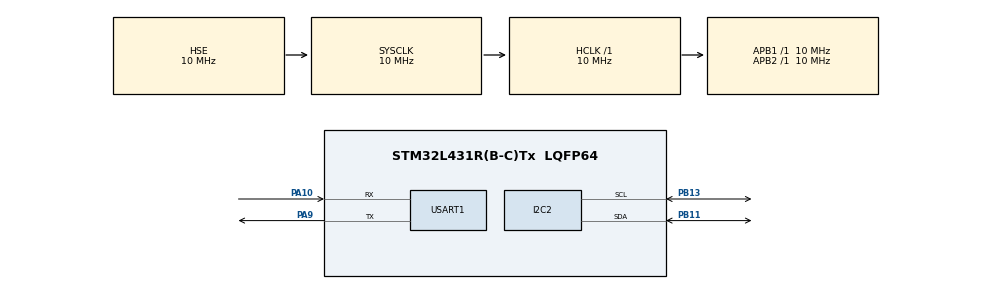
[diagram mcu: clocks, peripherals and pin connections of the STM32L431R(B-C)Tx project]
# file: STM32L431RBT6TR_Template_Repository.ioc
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FREERTOS.Tasks01=defaultTask,0,192,StartDefaultTask,Default,NULL,Dynamic,NULL,NULL
FREERTOS.configMINIMAL_STACK_SIZE=192
FREERTOS.configTOTAL_HEAP_SIZE=40000
FREERTOS.configUSE_NEWLIB_REENTRANT=1
FREERTOS.configUSE_TIMERS=1
I2C2.Timing=0x00302833
IWDG.Prescaler=IWDG_PRESCALER_16
Mcu.Family=STM32L4
Mcu.Name=STM32L431R(B-C)Tx
Mcu.Package=LQFP64
NVIC.PriorityGroup=NVIC_PRIORITYGROUP_4
NVIC.TIM1_UP_TIM16_IRQn=true\:15\:0\:false\:false\:true\:false\:false\:true\:true
NVIC.TimeBase=TIM1_UP_TIM16_IRQn
NVIC.TimeBaseIP=TIM1
NVIC.USART1_IRQn=true\:5\:0\:false\:false\:true\:true\:true\:true\:true
PA10.Mode=Asynchronous
PA10.Signal=USART1_RX
PA9.Mode=Asynchronous
PA9.Signal=USART1_TX
PB11.GPIO_Pu=GPIO_PULLUP
PB11.Mode=I2C
PB11.Signal=I2C2_SDA
PB13.GPIO_Pu=GPIO_PULLUP
PB13.Mode=I2C
PB13.Signal=I2C2_SCL
PH0-OSC_IN\ (PH0).Mode=HSE-External-Oscillator
PH0-OSC_IN\ (PH0).Signal=RCC_OSC_IN
PH1-OSC_OUT\ (PH1).Mode=HSE-External-Oscillator
PH1-OSC_OUT\ (PH1).Signal=RCC_OSC_OUT
ProjectManager.HeapSize=0x200
ProjectManager.StackSize=0x400
ProjectManager.TargetToolchain=STM32CubeIDE
RCC.ADCFreq_Value=16000000
RCC.AHBFreq_Value=10000000
RCC.APB1Freq_Value=10000000
RCC.APB1TimFreq_Value=10000000
RCC.APB2Freq_Value=10000000
RCC.APB2TimFreq_Value=10000000
RCC.CortexFreq_Value=10000000
RCC.HCLKFreq_Value=10000000
RCC.HSE_VALUE=10000000
RCC.HSI48_VALUE=48000000
RCC.HSI_VALUE=16000000
RCC.LSE_VALUE=32768
RCC.MSI_VALUE=4000000
RCC.SYSCLKFreq_VALUE=10000000
RCC.SYSCLKSource=RCC_SYSCLKSOURCE_HSE
RCC.VCOOutputFreq_Value=32000000
USART1.VirtualMode-Asynchronous=VM_ASYNC
VP_CRC_VS_CRC.Mode=CRC_Activate
VP_FREERTOS_VS_CMSIS_V1.Mode=CMSIS_V1
VP_IWDG_VS_IWDG.Mode=IWDG_Activate
VP_SYS_VS_tim1.Mode=TIM1
board=custom

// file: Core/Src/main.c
/* USER CODE BEGIN Header */
/**
  ******************************************************************************
  * @file           : main.c
  * @brief          : Main program body
  ******************************************************************************
  * @attention
  *
  * Copyright (c) 2025 STMicroelectronics.
  * All rights reserved.
  *
  * This software is licensed under terms that can be found in the LICENSE file
  * in the root directory of this software component.
  * If no LICENSE file comes with this software, it is provided AS-IS.
  *
  ******************************************************************************
  */
/* USER CODE END Header */
#include "main.h"
#include "cmsis_os.h"

/* USER CODE BEGIN Includes */
#include "RunInterface.hpp"
/* USER CODE END Includes */

CRC_HandleTypeDef hcrc;

I2C_HandleTypeDef hi2c2;

IWDG_HandleTypeDef hiwdg;

osThreadId defaultTaskHandle;

void SystemClock_Config(void);
static void MX_GPIO_Init(void);
static void MX_CRC_Init(void);
static void MX_USART1_UART_Init(void);
static void MX_I2C2_Init(void);
static void MX_IWDG_Init(void);
void StartDefaultTask(void const * argument);

int main(void)
{

  /* MCU Configuration--------------------------------------------------------*/

  /* Reset of all peripherals, Initializes the Flash interface and the Systick. */
  HAL_Init();

  /* Configure the system clock */
  SystemClock_Config();

  /* Initialize all configured peripherals */
  MX_GPIO_Init();
  MX_CRC_Init();
  MX_USART1_UART_Init();
  MX_I2C2_Init();
  MX_IWDG_Init();
  /* USER CODE BEGIN 2 */
  run_interface();
  #if 0
  /* USER CODE END 2 */

  /* Create the thread(s) */
  /* definition and creation of defaultTask */
  osThreadDef(defaultTask, StartDefaultTask, osPriorityNormal, 0, 192);
  defaultTaskHandle = osThreadCreate(osThread(defaultTask), NULL);

  /* Start scheduler */
  osKernelStart();

  /* We should never get here as control is now taken by the scheduler */

  /* Infinite loop */
  while (1)
  {

    /* USER CODE BEGIN 3 */
  }
#endif
  /* USER CODE END 3 */
}

void SystemClock_Config(void)
{
  RCC_OscInitTypeDef RCC_OscInitStruct = {0};
  RCC_ClkInitTypeDef RCC_ClkInitStruct = {0};

  /** Configure the main internal regulator output voltage
  */
  if (HAL_PWREx_ControlVoltageScaling(PWR_REGULATOR_VOLTAGE_SCALE1) != HAL_OK)
  {
    Error_Handler();
  }

  /** Initializes the RCC Oscillators according to the specified parameters
  * in the RCC_OscInitTypeDef structure.
  */
  RCC_OscInitStruct.OscillatorType = RCC_OSCILLATORTYPE_LSI|RCC_OSCILLATORTYPE_HSE;
  RCC_OscInitStruct.HSEState = RCC_HSE_ON;
  RCC_OscInitStruct.LSIState = RCC_LSI_ON;
  RCC_OscInitStruct.PLL.PLLState = RCC_PLL_NONE;
  if (HAL_RCC_OscConfig(&RCC_OscInitStruct) != HAL_OK)
  {
    Error_Handler();
  }

  /** Initializes the CPU, AHB and APB buses clocks
  */
  RCC_ClkInitStruct.ClockType = RCC_CLOCKTYPE_HCLK|RCC_CLOCKTYPE_SYSCLK
                              |RCC_CLOCKTYPE_PCLK1|RCC_CLOCKTYPE_PCLK2;
  RCC_ClkInitStruct.SYSCLKSource = RCC_SYSCLKSOURCE_HSE;
  RCC_ClkInitStruct.AHBCLKDivider = RCC_SYSCLK_DIV1;
  RCC_ClkInitStruct.APB1CLKDivider = RCC_HCLK_DIV1;
  RCC_ClkInitStruct.APB2CLKDivider = RCC_HCLK_DIV1;

  if (HAL_RCC_ClockConfig(&RCC_ClkInitStruct, FLASH_LATENCY_0) != HAL_OK)
  {
    Error_Handler();
  }
}

static void MX_CRC_Init(void)
{

  hcrc.Instance = CRC;
  hcrc.Init.DefaultPolynomialUse = DEFAULT_POLYNOMIAL_ENABLE;
  hcrc.Init.DefaultInitValueUse = DEFAULT_INIT_VALUE_ENABLE;
  hcrc.Init.InputDataInversionMode = CRC_INPUTDATA_INVERSION_NONE;
  hcrc.Init.OutputDataInversionMode = CRC_OUTPUTDATA_INVERSION_DISABLE;
  hcrc.InputDataFormat = CRC_INPUTDATA_FORMAT_BYTES;
  if (HAL_CRC_Init(&hcrc) != HAL_OK)
  {
    Error_Handler();
  }

}

static void MX_I2C2_Init(void)
{

  hi2c2.Instance = I2C2;
  hi2c2.Init.Timing = 0x00302833;
  hi2c2.Init.OwnAddress1 = 0;
  hi2c2.Init.AddressingMode = I2C_ADDRESSINGMODE_7BIT;
  hi2c2.Init.DualAddressMode = I2C_DUALADDRESS_DISABLE;
  hi2c2.Init.OwnAddress2 = 0;
  hi2c2.Init.OwnAddress2Masks = I2C_OA2_NOMASK;
  hi2c2.Init.GeneralCallMode = I2C_GENERALCALL_DISABLE;
  hi2c2.Init.NoStretchMode = I2C_NOSTRETCH_DISABLE;
  if (HAL_I2C_Init(&hi2c2) != HAL_OK)
  {
    Error_Handler();
  }

  /** Configure Analogue filter
  */
  if (HAL_I2CEx_ConfigAnalogFilter(&hi2c2, I2C_ANALOGFILTER_ENABLE) != HAL_OK)
  {
    Error_Handler();
  }

  /** Configure Digital filter
  */
  if (HAL_I2CEx_ConfigDigitalFilter(&hi2c2, 0) != HAL_OK)
  {
    Error_Handler();
  }

}

static void MX_IWDG_Init(void)
{

  hiwdg.Instance = IWDG;
  hiwdg.Init.Prescaler = IWDG_PRESCALER_16;
  hiwdg.Init.Window = 4095;
  hiwdg.Init.Reload = 4095;
  if (HAL_IWDG_Init(&hiwdg) != HAL_OK)
  {
    Error_Handler();
  }
  /* USER CODE BEGIN IWDG_Init 2 */
  HAL_IWDG_Refresh(&hiwdg);
  /* USER CODE END IWDG_Init 2 */

}

static void MX_USART1_UART_Init(void)
{

  LL_USART_InitTypeDef USART_InitStruct = {0};

  LL_GPIO_InitTypeDef GPIO_InitStruct = {0};
  RCC_PeriphCLKInitTypeDef PeriphClkInit = {0};

  /** Initializes the peripherals clock
  */
  PeriphClkInit.PeriphClockSelection = RCC_PERIPHCLK_USART1;
  PeriphClkInit.Usart1ClockSelection = RCC_USART1CLKSOURCE_PCLK2;
  if (HAL_RCCEx_PeriphCLKConfig(&PeriphClkInit) != HAL_OK)
  {
    Error_Handler();
  }

  /* Peripheral clock enable */
  LL_APB2_GRP1_EnableClock(LL_APB2_GRP1_PERIPH_USART1);

  LL_AHB2_GRP1_EnableClock(LL_AHB2_GRP1_PERIPH_GPIOA);
  /**USART1 GPIO Configuration
  PA9   ------> USART1_TX
  PA10   ------> USART1_RX
  */
  GPIO_InitStruct.Pin = LL_GPIO_PIN_9|LL_GPIO_PIN_10;
  GPIO_InitStruct.Mode = LL_GPIO_MODE_ALTERNATE;
  GPIO_InitStruct.Speed = LL_GPIO_SPEED_FREQ_VERY_HIGH;
  GPIO_InitStruct.OutputType = LL_GPIO_OUTPUT_PUSHPULL;
  GPIO_InitStruct.Pull = LL_GPIO_PULL_NO;
  GPIO_InitStruct.Alternate = LL_GPIO_AF_7;
  LL_GPIO_Init(GPIOA, &GPIO_InitStruct);

  /* USART1 interrupt Init */
  NVIC_SetPriority(USART1_IRQn, NVIC_EncodePriority(NVIC_GetPriorityGrouping(),5, 0));
  NVIC_EnableIRQ(USART1_IRQn);

  USART_InitStruct.BaudRate = 115200;
  USART_InitStruct.DataWidth = LL_USART_DATAWIDTH_8B;
  USART_InitStruct.StopBits = LL_USART_STOPBITS_1;
  USART_InitStruct.Parity = LL_USART_PARITY_NONE;
  USART_InitStruct.TransferDirection = LL_USART_DIRECTION_TX_RX;
  USART_InitStruct.HardwareFlowControl = LL_USART_HWCONTROL_NONE;
  USART_InitStruct.OverSampling = LL_USART_OVERSAMPLING_16;
  LL_USART_Init(USART1, &USART_InitStruct);
  LL_USART_ConfigAsyncMode(USART1);
  LL_USART_Enable(USART1);

}

static void MX_GPIO_Init(void)
{

  /* GPIO Ports Clock Enable */
  __HAL_RCC_GPIOH_CLK_ENABLE();
  __HAL_RCC_GPIOB_CLK_ENABLE();
  __HAL_RCC_GPIOA_CLK_ENABLE();

}

void StartDefaultTask(void const * argument)
{
  for(;;)
  {
    osDelay(1);
  }
}

void HAL_TIM_PeriodElapsedCallback(TIM_HandleTypeDef *htim)
{
  if (htim->Instance == TIM1) {
    HAL_IncTick();
  }
}

void Error_Handler(void)
{
  __disable_irq();
  while (1)
  {
  }
}
